VERSION "A"

NS_ :

BS_:

BU_:

BO_ 0 MainControllerHeartbeat: 2 Vector__XXX
 SG_ MainControllerCounter : 8|8@1+ (1,0) [0|255] "" Vector__XXX
 SG_ MainControllerStatus : 0|8@1+ (1,0) [0|255] "" Vector__XXX

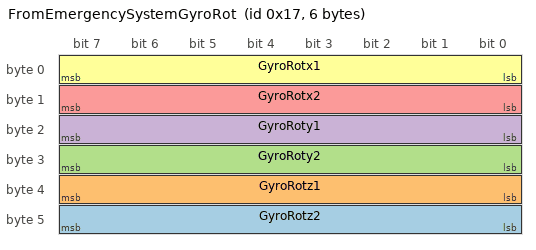
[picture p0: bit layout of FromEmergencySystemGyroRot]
BO_ 23 FromEmergencySystemGyroRot: 6 Vector__XXX
 SG_ GyroRotz2 : 40|8@1+ (1,0) [0|255] "" Vector__XXX
 SG_ GyroRotz1 : 32|8@1+ (1,0) [0|255] "" Vector__XXX
 SG_ GyroRoty2 : 24|8@1+ (1,0) [0|255] "" Vector__XXX
 SG_ GyroRoty1 : 16|8@1+ (1,0) [0|255] "" Vector__XXX
 SG_ GyroRotx2 : 8|8@1+ (1,0) [0|255] "" Vector__XXX
 SG_ GyroRotx1 : 0|8@1+ (1,0) [0|255] "" Vector__XXX

BA_DEF_  "BusType" STRING ;
BA_DEF_DEF_  "BusType" "CAN";
